# MCASP0_CFG register map
Vendor: Texas Instruments
Peripheral module from a debugger description file (folder J7VCL).
Registers are 32-bit, read-write, reset 0x0 unless marked. A register's access mark holds for its fields unless they carry their own. Offsets are as the file gives them; lines under a group give offsets from that group; [hi:lo] are bit positions; {n}, {i} and the like mark numbered series; 'fields as' and 'values as' point back to an identical list; <NAME> marks a mode.

## MCASP0_CFG (part 1 of 3)
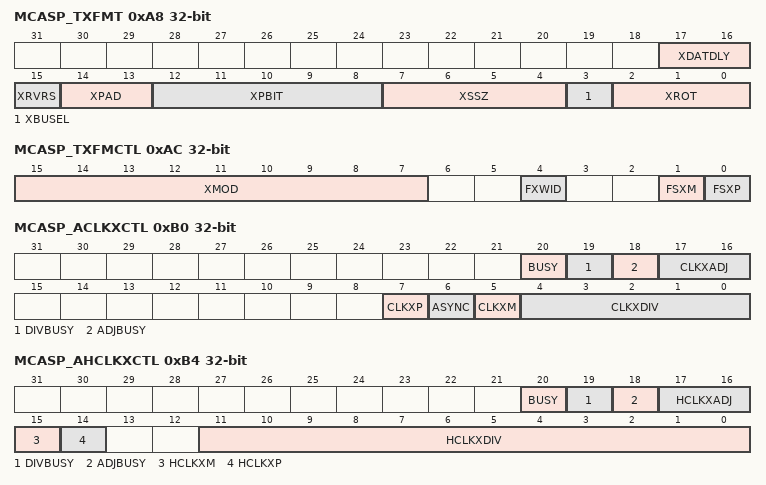
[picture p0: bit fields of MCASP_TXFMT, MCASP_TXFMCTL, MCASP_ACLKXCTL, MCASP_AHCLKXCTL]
0xA8 MCASP_TXFMT
  [17:16] XDATDLY — Transmit sync bit delay.0h = 0-bit delay. The first transmit data bit, AXRn, occurs in same ACLKX cycle as the transmit frame sync (AFSX). 1h = 1-bit delay. The first transmit data bit, AXRn, occurs one ACLKX cycle after the transmit frame sync (AFSX). 2h = 2-bit delay. The first transmit data bit, AXRn, occurs two ACLKX cycles after the transmit frame sync (AFSX). 3h = Reserved.
  [15] XRVRS — Transmit serial bitstream order.0h = Bitstream is LSB first. No bit reversal is performed in transmit format bit reverse unit. 1h = Bitstream is MSB first. Bit reversal is performed in transmit format bit reverse unit.
  [14:13] XPAD — Pad value for extra bits in slot not belonging to word defined by MCASP_XMASK. This field only applies to bits when MCASP_XMASK[n] = 0. 0h = Pad extra bits with 0. 1h = Pad extra bits with 1. 2h = Pad extra bits with one of the bits from the word as specified by XPBIT bits. 3h = Reserved.
  [12:8] XPBIT — XPBIT value determines which bit [as written by the CPU or DMA to XBUF[n]] is used to pad the extra bits before shifting. This field only applies when XPAD = 2h. 0h = Pad with bit 0 value. 1h = Pad with bit 1 to bit 31 value from 1h to 1Fh.
  [7:4] XSSZ — Transmit slot size.0h = Reserved. 1h = Reserved. 2h = Reserved. 3h = Slot size is 8 bits. 4h = Reserved. 5h = Slot size is 12 bits. 6h = Reserved. 7h = Slot size is 16 bits. 8h = Reserved. 9h = Slot size is 20 bits. Ah = Reserved. Bh = Slot size is 24 bits. Ch = Reserved. Dh = Slot size is 28 bits. Eh = Reserved. Fh = Slot size is 32 bits.
  [3] XBUSEL — Selects whether writes to serializer buffer XRBUF[n] originate from the configuration bus [CFG] or the data [DAT] port.0h = Writes to XRBUF[n] originate from the data port. Writes to XRBUF[n] from the configuration bus are ignored with no effect to the McASP. 1h = Writes to XRBUF[n] originate from the configuration bus. Writes to XRBUF[n] from the data port are ignored with no effect to the McASP.
  [2:0] XROT — Right-rotation value for transmit rotate right format unit.0h = Rotate right by 0 (no rotation). 1h = Rotate right by 4 bit positions. 2h = Rotate right by 8 bit positions. 3h = Rotate right by 12 bit positions. 4h = Rotate right by 16 bit positions. 5h = Rotate right by 20 bit positions. 6h = Rotate right by 24 bit positions. 7h = Rotate right by 28 bit positions.
0xAC MCASP_TXFMCTL
  [15:7] XMOD — Transmit frame sync mode select bits. 1FFh = Reserved from 181h to 1FFh. 0h = Burst mode. 1h = Reserved. 2h = 2-slot TDM (I2S mode) to 32-slot TDM from 2h to 20h. 21h = Reserved from 21h to 17Fh. 180h = 384-slot DIT mode. 181h = Reserved from 181h to 1FFh.
  [4] FXWID — Transmit frame sync width select bit indicates the width of the transmit frame sync [AFSX] during its active period.0h = Single bit. 1h = Single word.
  [1] FSXM — Transmit frame sync generation select bit.0h = Externally-generated transmit frame sync. 1h = Internally-generated transmit frame sync.
  [0] FSXP — Transmit frame sync polarity select bit.0h = A rising edge on transmit frame sync (AFSX) indicates the beginning of a frame. 1h = A falling edge on transmit frame sync (AFSX) indicates the beginning of a frame.
0xB0 MCASP_ACLKXCTL access per field
  [20] BUSY rw — The logic OR of bits 18 and 19, indicating that some clk change is in progress when high
  [19] DIVBUSY rw — Divider change in progress (same behavior as bit 18)
  [18] ADJBUSY rw — one-shot adj in progress (a BUSY bit that is set when an adj is in progress, cleared when the adjustment has taken effect)
  [17:16] CLKXADJ wo — CLKXDIV one-shot adjustment control. If CLKXDIV is set such that there are “m” input clocks per one output clock, then for one output cycle: 0h = (m+0) input clocks per output clock 1h = (m-1) input clocks per output clock 2h = (m+1) input clocks per output clock 3h = (m+0) input clocks per output clock
  [7] CLKXP rw — Transmit bitstream clock polarity select bit.0h = Rising edge. External receiver samples data on the falling edge of the serial clock, so the transmitter must shift data out on the rising edge of the serial clock. 1h = Falling edge. External receiver samples data on the rising edge of the serial clock, so the transmitter must shift data out on the falling edge of the serial clock.
  [6] ASYNC rw — Transmit/receive operation asynchronous enable bit.0h = Synchronous. Transmit clock and frame sync provides the source for both the transmit and receive sections. 1h = Asynchronous. Separate clock and frame sync used by transmit and receive sections.
  [5] CLKXM rw — Transmit bit clock source bit.0h = External transmit clock source from ACLKX pin. 1h = Internal transmit clock source from output of programmable bit clock divider.
  [4:0] CLKXDIV rw — Transmit bit clock divide ratio bits determine the divide-down ratio from AHCLKX to ACLKX.0h = Divide-by-1. 1h = Divide-by-2. 2h = Divide-by-3 to divide-by-32 from 2h to 1Fh.
0xB4 MCASP_AHCLKXCTL access per field
  [20] BUSY rw — The logic OR of bits 18 and 19, indicating that some clk change is in progress when high
  [19] DIVBUSY rw — Divider change in progress (same behavior as bit 18)
  [18] ADJBUSY rw — one-shot adj in progress (a BUSY bit that is set when an adj is in progress, cleared when the adjustment has taken effect)
  [17:16] HCLKXADJ wo — CLKXDIV one-shot adjustment control. If CLKXDIV is set such that there are “m” input clocks per one output clock, then for one output cycle: 0h = (m+0) input clocks per output clock 1h = (m-1) input clocks per output clock 2h = (m+1) input clocks per output clock 3h = (m+0) input clocks per output clock
  [15] HCLKXM rw — Transmit high-frequency clock source bit.0h = External transmit high-frequency clock source from AHCLKX pin. 1h = Internal transmit high-frequency clock source from output of programmable high clock divider.
  [14] HCLKXP rw — Transmit bitstream high-frequency clock polarity select bit.0h = AHCLKX is not inverted before programmable bit clock divider. In the special case where the transmit bit clock (ACLKX) is internally generated and the programmable bit clock divider is set to divide-by-1 (CLKXDIV = 0 in 1h = AHCLKX is inverted before programmable bit clock divider. In the special case where the transmit bit clock (ACLKX) is internally generated and the programmable bit clock divider is set to divide-by-1 (CLKXDIV = 0 in
  [11:0] HCLKXDIV rw — Transmit high-frequency clock divide ratio bits determine the divide-down ratio from AUXCLK to AHCLKX.0h = Divide-by-1. 1h = Divide-by-2. 2h = Divide-by-3 to divide-by-4096 from 2h to FFFh.
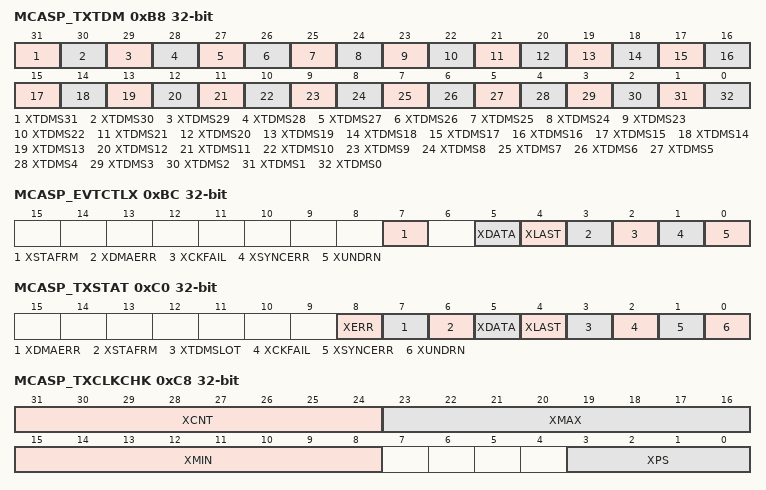
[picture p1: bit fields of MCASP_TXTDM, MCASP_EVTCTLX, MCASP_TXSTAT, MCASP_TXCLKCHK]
0xB8 MCASP_TXTDM
  [31] XTDMS31 — Transmitter mode during TDM time slot 31.0h = Transmit TDM time slot 31 is inactive. The transmit serializer does not shift out data during this slot. 1h = Transmit TDM time slot 31 is active. The transmit serializer shifts out data during this slot according to the serializer control register (SRCTL).
  [30] XTDMS30 — Transmitter mode during TDM time slot 30.0h = Transmit TDM time slot 30 is inactive. The transmit serializer does not shift out data during this slot. 1h = Transmit TDM time slot 30 is active. The transmit serializer shifts out data during this slot according to the serializer control register (SRCTL).
  [29] XTDMS29 — Transmitter mode during TDM time slot 29.0h = Transmit TDM time slot 29 is inactive. The transmit serializer does not shift out data during this slot. 1h = Transmit TDM time slot 29 is active. The transmit serializer shifts out data during this slot according to the serializer control register (SRCTL).
  [28] XTDMS28 — Transmitter mode during TDM time slot 28.0h = Transmit TDM time slot 28 is inactive. The transmit serializer does not shift out data during this slot. 1h = Transmit TDM time slot 28 is active. The transmit serializer shifts out data during this slot according to the serializer control register (SRCTL).
  [27] XTDMS27 — Transmitter mode during TDM time slot 27.0h = Transmit TDM time slot 27 is inactive. The transmit serializer does not shift out data during this slot. 1h = Transmit TDM time slot 27 is active. The transmit serializer shifts out data during this slot according to the serializer control register (SRCTL).
  [26] XTDMS26 — Transmitter mode during TDM time slot 26.0h = Transmit TDM time slot 26 is inactive. The transmit serializer does not shift out data during this slot. 1h = Transmit TDM time slot 26 is active. The transmit serializer shifts out data during this slot according to the serializer control register (SRCTL).
  [25] XTDMS25 — Transmitter mode during TDM time slot 25.0h = Transmit TDM time slot 25 is inactive. The transmit serializer does not shift out data during this slot. 1h = Transmit TDM time slot 25 is active. The transmit serializer shifts out data during this slot according to the serializer control register (SRCTL).
  [24] XTDMS24 — Transmitter mode during TDM time slot 24.0h = Transmit TDM time slot 24 is inactive. The transmit serializer does not shift out data during this slot. 1h = Transmit TDM time slot 24 is active. The transmit serializer shifts out data during this slot according to the serializer control register (SRCTL).
  [23] XTDMS23 — Transmitter mode during TDM time slot 23.0h = Transmit TDM time slot 23 is inactive. The transmit serializer does not shift out data during this slot. 1h = Transmit TDM time slot 23 is active. The transmit serializer shifts out data during this slot according to the serializer control register (SRCTL).
  [22] XTDMS22 — Transmitter mode during TDM time slot 22.0h = Transmit TDM time slot 22 is inactive. The transmit serializer does not shift out data during this slot. 1h = Transmit TDM time slot 22 is active. The transmit serializer shifts out data during this slot according to the serializer control register (SRCTL).
  [21] XTDMS21 — Transmitter mode during TDM time slot 21.0h = Transmit TDM time slot 21 is inactive. The transmit serializer does not shift out data during this slot. 1h = Transmit TDM time slot 21 is active. The transmit serializer shifts out data during this slot according to the serializer control register (SRCTL).
  [20] XTDMS20 — Transmitter mode during TDM time slot 20.0h = Transmit TDM time slot 20 is inactive. The transmit serializer does not shift out data during this slot. 1h = Transmit TDM time slot 20 is active. The transmit serializer shifts out data during this slot according to the serializer control register (SRCTL).
  [19] XTDMS19 — Transmitter mode during TDM time slot 19.0h = Transmit TDM time slot 19 is inactive. The transmit serializer does not shift out data during this slot. 1h = Transmit TDM time slot 19 is active. The transmit serializer shifts out data during this slot according to the serializer control register (SRCTL).
  [18] XTDMS18 — Transmitter mode during TDM time slot 18.0h = Transmit TDM time slot 18 is inactive. The transmit serializer does not shift out data during this slot. 1h = Transmit TDM time slot 18 is active. The transmit serializer shifts out data during this slot according to the serializer control register (SRCTL).
  [17] XTDMS17 — Transmitter mode during TDM time slot 17.0h = Transmit TDM time slot 17 is inactive. The transmit serializer does not shift out data during this slot. 1h = Transmit TDM time slot 17 is active. The transmit serializer shifts out data during this slot according to the serializer control register (SRCTL).
  [16] XTDMS16 — Transmitter mode during TDM time slot 16.0h = Transmit TDM time slot 16 is inactive. The transmit serializer does not shift out data during this slot. 1h = Transmit TDM time slot 16 is active. The transmit serializer shifts out data during this slot according to the serializer control register (SRCTL).
  [15] XTDMS15 — Transmitter mode during TDM time slot 15.0h = Transmit TDM time slot 15 is inactive. The transmit serializer does not shift out data during this slot. 1h = Transmit TDM time slot 15 is active. The transmit serializer shifts out data during this slot according to the serializer control register (SRCTL).
  [14] XTDMS14 — Transmitter mode during TDM time slot 14.0h = Transmit TDM time slot 14 is inactive. The transmit serializer does not shift out data during this slot. 1h = Transmit TDM time slot 14 is active. The transmit serializer shifts out data during this slot according to the serializer control register (SRCTL).
  [13] XTDMS13 — Transmitter mode during TDM time slot 13.0h = Transmit TDM time slot 13 is inactive. The transmit serializer does not shift out data during this slot. 1h = Transmit TDM time slot 13 is active. The transmit serializer shifts out data during this slot according to the serializer control register (SRCTL).
  [12] XTDMS12 — Transmitter mode during TDM time slot 12.0h = Transmit TDM time slot 12 is inactive. The transmit serializer does not shift out data during this slot. 1h = Transmit TDM time slot 12 is active. The transmit serializer shifts out data during this slot according to the serializer control register (SRCTL).
  [11] XTDMS11 — Transmitter mode during TDM time slot 11.0h = Transmit TDM time slot 11 is inactive. The transmit serializer does not shift out data during this slot. 1h = Transmit TDM time slot 11 is active. The transmit serializer shifts out data during this slot according to the serializer control register (SRCTL).
  [10] XTDMS10 — Transmitter mode during TDM time slot 10.0h = Transmit TDM time slot 10 is inactive. The transmit serializer does not shift out data during this slot. 1h = Transmit TDM time slot 10 is active. The transmit serializer shifts out data during this slot according to the serializer control register (SRCTL).
  [9] XTDMS9 — Transmitter mode during TDM time slot 9.0h = Transmit TDM time slot 9 is inactive. The transmit serializer does not shift out data during this slot. 1h = Transmit TDM time slot 9 is active. The transmit serializer shifts out data during this slot according to the serializer control register (SRCTL).
  [8] XTDMS8 — Transmitter mode during TDM time slot 8.0h = Transmit TDM time slot 8 is inactive. The transmit serializer does not shift out data during this slot. 1h = Transmit TDM time slot 8 is active. The transmit serializer shifts out data during this slot according to the serializer control register (SRCTL).
  [7] XTDMS7 — Transmitter mode during TDM time slot 7.0h = Transmit TDM time slot 7 is inactive. The transmit serializer does not shift out data during this slot. 1h = Transmit TDM time slot 7 is active. The transmit serializer shifts out data during this slot according to the serializer control register (SRCTL).
  [6] XTDMS6 — Transmitter mode during TDM time slot 6.0h = Transmit TDM time slot 6 is inactive. The transmit serializer does not shift out data during this slot. 1h = Transmit TDM time slot 6 is active. The transmit serializer shifts out data during this slot according to the serializer control register (SRCTL).
  [5] XTDMS5 — Transmitter mode during TDM time slot 5.0h = Transmit TDM time slot 5 is inactive. The transmit serializer does not shift out data during this slot. 1h = Transmit TDM time slot 5 is active. The transmit serializer shifts out data during this slot according to the serializer control register (SRCTL).
  [4] XTDMS4 — Transmitter mode during TDM time slot 4.0h = Transmit TDM time slot 4 is inactive. The transmit serializer does not shift out data during this slot. 1h = Transmit TDM time slot 4 is active. The transmit serializer shifts out data during this slot according to the serializer control register (SRCTL).
  [3] XTDMS3 — Transmitter mode during TDM time slot 3.0h = Transmit TDM time slot 3 is inactive. The transmit serializer does not shift out data during this slot. 1h = Transmit TDM time slot 3 is active. The transmit serializer shifts out data during this slot according to the serializer control register (SRCTL).
  [2] XTDMS2 — Transmitter mode during TDM time slot 2.0h = Transmit TDM time slot 2 is inactive. The transmit serializer does not shift out data during this slot. 1h = Transmit TDM time slot 2 is active. The transmit serializer shifts out data during this slot according to the serializer control register (SRCTL).
  [1] XTDMS1 — Transmitter mode during TDM time slot 1.0h = Transmit TDM time slot 1 is inactive. The transmit serializer does not shift out data during this slot. 1h = Transmit TDM time slot 1 is active. The transmit serializer shifts out data during this slot according to the serializer control register (SRCTL).
  [0] XTDMS0 — Transmitter mode during TDM time slot 0.0h = Transmit TDM time slot 0 is inactive. The transmit serializer does not shift out data during this slot. 1h = Transmit TDM time slot 0 is active. The transmit serializer shifts out data during this slot according to the serializer control register (SRCTL).
0xBC MCASP_EVTCTLX
  [7] XSTAFRM — Transmit start of frame interrupt enable bit.0h = Interrupt is disabled. A transmit start of frame interrupt does not generate a McASP transmit interrupt (XINT). 1h = Interrupt is enabled. A transmit start of frame interrupt generates a McASP transmit interrupt (XINT).
  [5] XDATA — Transmit data ready interrupt enable bit.0h = Interrupt is disabled. A transmit data ready interrupt does not generate a McASP transmit interrupt (XINT). 1h = Interrupt is enabled. A transmit data ready interrupt generates a McASP transmit interrupt (XINT).
  [4] XLAST — Transmit last slot interrupt enable bit.0h = Interrupt is disabled. A transmit last slot interrupt does not generate a McASP transmit interrupt (XINT). 1h = Interrupt is enabled. A transmit last slot interrupt generates a McASP transmit interrupt (XINT).
  [3] XDMAERR — Transmit DMA error interrupt enable bit.0h = Interrupt is disabled. A transmit DMA error interrupt does not generate a McASP transmit interrupt (XINT). 1h = Interrupt is enabled. A transmit DMA error interrupt generates a McASP transmit interrupt (XINT).
  [2] XCKFAIL — Transmit clock failure interrupt enable bit.0h = Interrupt is disabled. A transmit clock failure interrupt does not generate a McASP transmit interrupt (XINT). 1h = Interrupt is enabled. A transmit clock failure interrupt generates a McASP transmit interrupt (XINT).
  [1] XSYNCERR — Unexpected transmit frame sync interrupt enable bit.0h = Interrupt is disabled. An unexpected transmit frame sync interrupt does not generate a McASP transmit interrupt (XINT). 1h = Interrupt is enabled. An unexpected transmit frame sync interrupt generates a McASP transmit interrupt (XINT).
  [0] XUNDRN — Transmitter underrun interrupt enable bit.0h = Interrupt is disabled. A transmitter underrun interrupt does not generate a McASP transmit interrupt (XINT). 1h = Interrupt is enabled. A transmitter underrun interrupt generates a McASP transmit interrupt (XINT).
0xC0 MCASP_TXSTAT
  [8] XERR — XERR bit always returns a logic-OR of: XUNDRN OR XSYNCERR OR XCKFAIL OR XDMAERR. Allows a single bit to be checked to determine if a transmitter error interrupt has occurred. 0h = No errors have occurred. 1h = An error has occurred.
  [7] XDMAERR — Transmit DMA error flag. XDMAERR is set when the CPU or DMA writes more serializers through the data port in a given time slot than were programmed as transmitters. Causes a transmit interrupt [XINT], if this bit is set and XDMAERR in MCASP_XINTCTL is set. This bit is cleared by writing a 1 to this bit. Writing a 0 has no effect. 0h = Transmit DMA error did not occur. 1h = Transmit DMA error did occur.
  [6] XSTAFRM — Transmit start of frame flag. Causes a transmit interrupt [XINT], if this bit is set and XSTAFRM in MCASP_XINTCTL is set. This bit is cleared by writing a 1 to this bit. Writing a 0 has no effect. 0h = No new transmit frame sync (AFSX) is detected. 1h = A new transmit frame sync (AFSX) is detected.
  [5] XDATA — Transmit data ready flag. Causes a transmit interrupt [XINT], if this bit is set and XDATA in MCASP_XINTCTL is set. This bit is cleared by writing a 1 to this bit. Writing a 0 has no effect. 0h = XBUF is written and is full. 1h = Data is copied from XBUF to XRSR. XBUF is empty and ready to be written. XDATA is also set when the transmit serializers are taken out of reset. When XDATA is set, it always causes a DMA event (AXEVT).
  [4] XLAST — Transmit last slot flag. XLAST is set along with XDATA, if the current slot is the last slot in a frame. Causes a transmit interrupt [XINT], if this bit is set and XLAST in MCASP_XINTCTL is set. This bit is cleared by writing a 1 to this bit. Writing a 0 has no effect. 0h = Current slot is not the last slot in a frame. 1h = Current slot is the last slot in a frame. XDATA is also set.
  [3] XTDMSLOT — Returns the LSB of MCASP_XSLOT. Allows a single read of MCASP_XSTAT to determine whether the current TDM time slot is even or odd. 0h = Current TDM time slot is odd. 1h = Current TDM time slot is even.
  [2] XCKFAIL — Transmit clock failure flag. XCKFAIL is set when the transmit clock failure detection circuit reports an error. Causes a transmit interrupt [XINT], if this bit is set and XCKFAIL in MCASP_XINTCTL is set. This bit is cleared by writing a 1 to this bit. Writing a 0 has no effect. 0h = Transmit clock failure did not occur. 1h = Transmit clock failure did occur.
  [1] XSYNCERR — Unexpected transmit frame sync flag. XSYNCERR is set when a new transmit frame sync [AFSX] occurs before it is expected. Causes a transmit interrupt [XINT], if this bit is set and XSYNCERR in MCASP_XINTCTL is set. This bit is cleared by writing a 1 to this bit. Writing a 0 has no effect. 0h = Unexpected transmit frame sync did not occur. 1h = Unexpected transmit frame sync did occur.
  [0] XUNDRN — Transmitter underrun flag. XUNDRN is set when the transmit serializer is instructed to transfer data from XBUF to XRSR, but XBUF has not yet been serviced with new data since the last transfer. Causes a transmit interrupt [XINT], if this bit is set and XUNDRN in MCASP_XINTCTL is set. This bit is cleared by writing a 1 to this bit. Writing a 0 has no effect. 0h = Transmitter underrun did not occur. 1h = Transmitter underrun did occur. For details on McASP action upon underrun conditions, see Buffer Underrun Error - Transmitter.
0xC4 MCASP_TXTDMSLOT ro
  [9:0] XSLOTCNT — Current transmit time slot count. Legal values: 0 to 383 [17Fh]. During reset, this counter value is 383 so the next count value, which is used to encode the first DIT group of data, will be 0 and encodes the B preamble. TDM function is not supported for &gt;32 time slots. However, TDM time slot counter may count to 383 when used to transmit a DIT block.
0xC8 MCASP_TXCLKCHK access per field
  [31:24] XCNT ro — Transmit clock count value [from previous measurement]. The clock circuit continually counts the number of system clocks for every 32 transmit high-frequency master clock [AHCLKX] signals, and stores the count in XCNT until the next measurement is taken.
  [23:16] XMAX rw — Transmit clock maximum boundary. This 8 bit unsigned value sets the maximum allowed boundary for the clock check counter after 32 transmit high-frequency master clock [AHCLKX] signals have been received. If the current counter value is greater than XMAX after counting 32 AHCLKX signals, XCKFAIL in MCASP_XSTAT is set. The comparison is performed using unsigned arithmetic.
  [15:8] XMIN rw — Transmit clock minimum boundary. This 8 bit unsigned value sets the minimum allowed boundary for the clock check counter after 32 transmit high-frequency master clock [AHCLKX] signals have been received. If XCNT is less than XMIN after counting 32 AHCLKX signals, XCKFAIL in MCASP_XSTAT is set. The comparison is performed using unsigned arithmetic.
  [3:0] XPS rw — Transmit clock check prescaler value. Fh = Reserved from 9h to Fh. 0h = MCASP system clock divided by 1. 1h = MCASP system clock divided by 2. 2h = MCASP system clock divided by 4. 3h = MCASP system clock divided by 8. 4h = MCASP system clock divided by 16. 5h = MCASP system clock divided by 32. 6h = MCASP system clock divided by 64. 7h = MCASP system clock divided by 128. 8h = MCASP system clock divided by 256. 9h = Reserved from 9h to Fh.
0xCC MCASP_XEVTCTL access per field
  [0] XDATDMA rw — Transmit data DMA request enable bit. If writing to this bit, always write the default value of 0. 0h = Transmit data DMA request is enabled. 1h = Reserved
0xD0 MCASP_CLKADJEN access per field
  [0] ENABLE rw — One-shot clock adjustment enable. 0 = One-shot clock adjustment is DISABLED. Writes to bits 17:16 of 1 = One-shot clock adjustment is ENABLED. Writes to bits 17:16 of
{0x100+4i} MCASP_DITCSRA{i} (i=0..5)
  [31:0] DITCSRA{i} — DIT left channel status registers.
{0x118+4i} MCASP_DITCSRB{i} (i=0..5)
  [31:0] DITCSRB{i} — DIT right channel status registers.
{0x130+4i} MCASP_DITUDRA{i} (i=0..5)
  [31:0] DITUDRA{i} — DIT left channel user data registers.
{0x148+4i} MCASP_DITUDRB{i} (i=0..5)
  [31:0] DITUDRB{i} — DIT right channel user data registers.
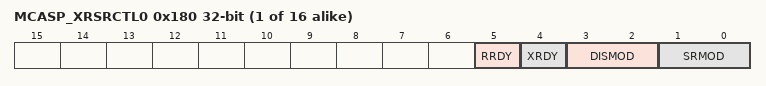
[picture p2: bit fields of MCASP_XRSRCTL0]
{0x180+4i} MCASP_XRSRCTL{i} access per field (i=0..15)
  [5] RRDY ro — Receive buffer ready bit. RRDY indicates the current receive buffer state. Always reads 0 when programmed as a transmitter or as inactive. If SRMOD bit is set to receive [2h], RRDY switches from 0 to 1 whenever data is transferred from XRSR to RBUF. 0h = Receive buffer (RBUF) is empty. 1h = Receive buffer (RBUF) contains data and needs to be read before the start of the next time slot or a receiver overrun occurs.
  [4] XRDY ro — Transmit buffer ready bit. XRDY indicates the current transmit buffer state. Always reads 0 when programmed as a receiver or as inactive. If SRMOD bit is set to transmit [1h], XRDY switches from 0 to 1 when XSRCLR in MCASP_GBLCTL is switched from 0 to 1 to indicate an empty transmitter. XRDY remains set until XSRCLR is forced to 0, data is written to the corresponding transmit buffer, or SRMOD bit is changed to receive [2h] or inactive [0]. 0h = Transmit buffer (XBUF) contains data. 1h = Transmit buffer (XBUF) is empty and needs to be written before the start of the next time slot or a transmit underrun occurs.
  [3:2] DISMOD rw — Serializer pin drive mode bit. Drive on pin when in inactive TDM slot of transmit mode or when serializer is inactive. This field only applies if the pin is configured as a McASP pin [MCASP_PFUNC = 0]. 0h = Drive on pin is 3-state. 1h = Reserved. 2h = Drive on pin is logic low. 3h = Drive on pin is logic high.
  [1:0] SRMOD rw — Serializer mode bit.0h = Serializer is inactive. 1h = Serializer is transmitter. 2h = Serializer is receiver. 3h = Reserved.
{0x200+4i} MCASP_TXBUF{i} (i=0..15)
  [31:0] XBUF{i} — Transmit buffers for serializers.
{0x280+4i} MCASP_RXBUF{i} (i=0..15)
  [31:0] RBUF{i} — Receive buffers for serializers.
